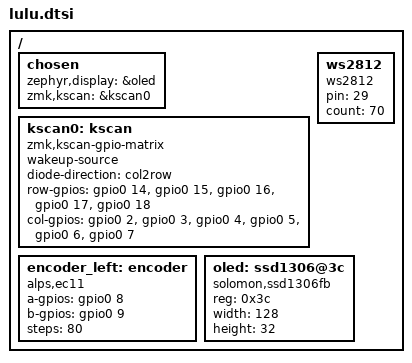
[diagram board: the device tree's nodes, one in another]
/*
 * Lulu RP2040 device tree for ZMK
 * Pin assignments match QMK config
 */

#include <dt-bindings/zmk/matrix_transform.h>

/ {
    chosen {
        zephyr,display = &oled;
        zmk,kscan = &kscan0;
    };

    kscan0: kscan {
        compatible = "zmk,kscan-gpio-matrix";
        wakeup-source;
        diode-direction = "col2row";
        row-gpios = <
            &gpio0 14 GPIO_ACTIVE_HIGH
            &gpio0 15 GPIO_ACTIVE_HIGH
            &gpio0 16 GPIO_ACTIVE_HIGH
            &gpio0 17 GPIO_ACTIVE_HIGH
            &gpio0 18 GPIO_ACTIVE_HIGH
        >;
        col-gpios = <
            &gpio0 2 GPIO_ACTIVE_HIGH
            &gpio0 3 GPIO_ACTIVE_HIGH
            &gpio0 4 GPIO_ACTIVE_HIGH
            &gpio0 5 GPIO_ACTIVE_HIGH
            &gpio0 6 GPIO_ACTIVE_HIGH
            &gpio0 7 GPIO_ACTIVE_HIGH
        >;
    };

    encoder_left: encoder {
        compatible = "alps,ec11";
        a-gpios = <&gpio0 8 GPIO_ACTIVE_HIGH>;
        b-gpios = <&gpio0 9 GPIO_ACTIVE_HIGH>;
        steps = <80>;
    };

    ws2812 {
        compatible = "ws2812";
        pin = <29>;
        count = <70>;
    };

    oled: ssd1306@3c {
        compatible = "solomon,ssd1306fb";
        reg = <0x3c>;
        width = <128>;
        height = <32>;
    };
}
